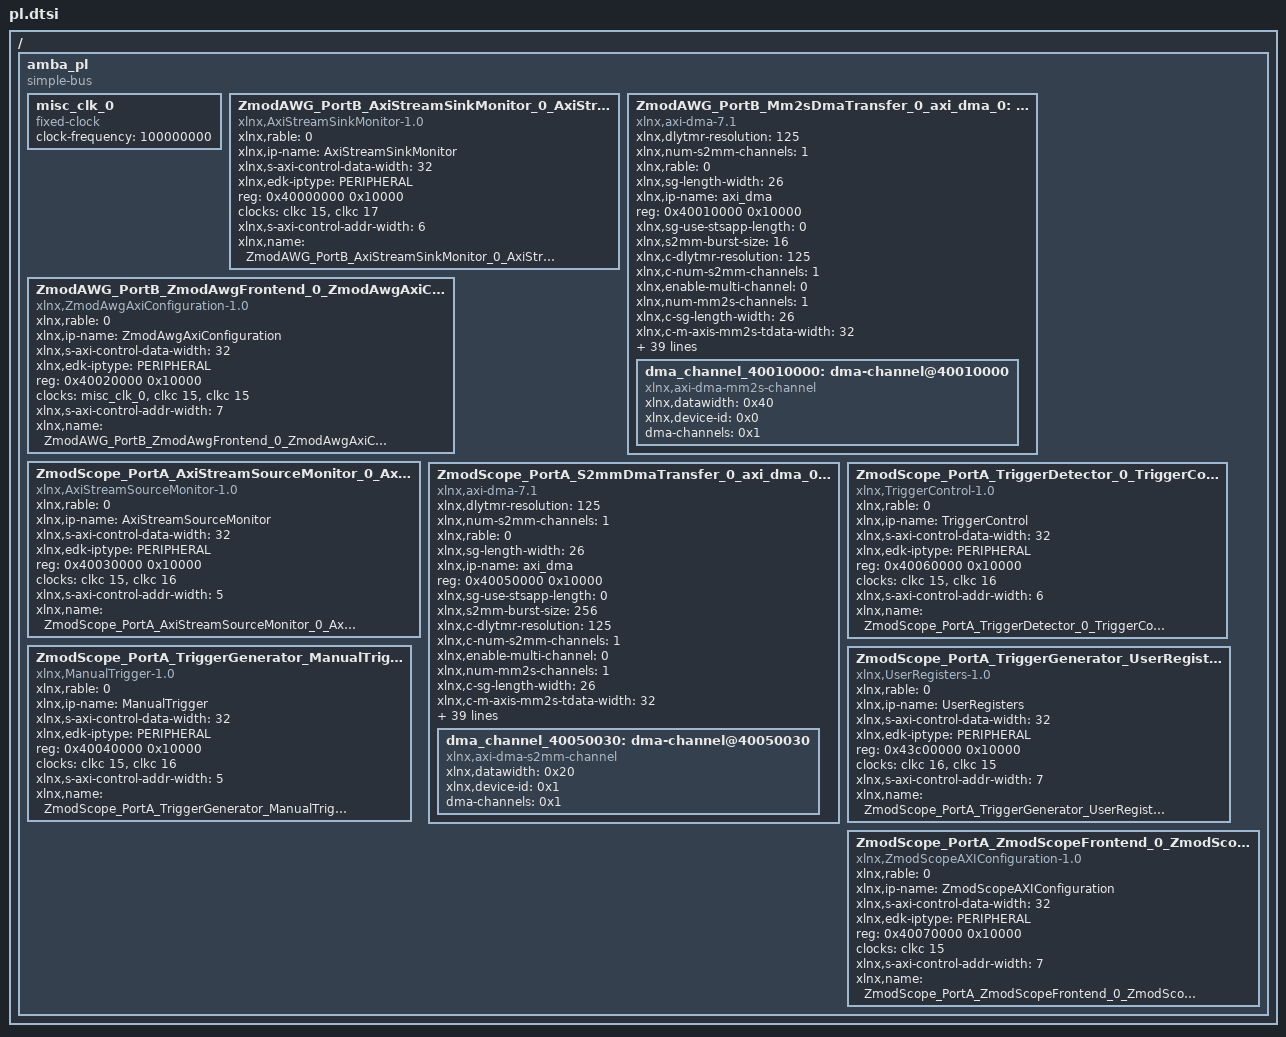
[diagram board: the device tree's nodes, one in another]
/ {
	amba_pl: amba_pl {
		ranges;
		compatible = "simple-bus";
		#address-cells = <1>;
		#size-cells = <1>;
		misc_clk_0: misc_clk_0 {
			compatible = "fixed-clock";
			clock-frequency = <100000000>;
			#clock-cells = <0>;
		};
		ZmodAWG_PortB_AxiStreamSinkMonitor_0_AxiStreamSinkMonitor_0: AxiStreamSinkMonitor@40000000 {
			xlnx,rable = <0>;
			compatible = "xlnx,AxiStreamSinkMonitor-1.0";
			status = "okay";
			clock-names = "s_axi_aclk" , "stream_clk";
			xlnx,ip-name = "AxiStreamSinkMonitor";
			xlnx,s-axi-control-data-width = <32>;
			xlnx,edk-iptype = "PERIPHERAL";
			reg = <0x40000000 0x10000>;
			clocks = <&clkc 15>, <&clkc 17>;
			xlnx,s-axi-control-addr-width = <6>;
			xlnx,name = "ZmodAWG_PortB_AxiStreamSinkMonitor_0_AxiStreamSinkMonitor_0";
		};
		ZmodAWG_PortB_Mm2sDmaTransfer_0_axi_dma_0: axi_dma@40010000 {
			xlnx,dlytmr-resolution = <125>;
			xlnx,num-s2mm-channels = <1>;
			xlnx,rable = <0>;
			xlnx,sg-length-width = <26>;
			xlnx,ip-name = "axi_dma";
			reg = <0x40010000 0x10000>;
			xlnx,sg-use-stsapp-length = <0>;
			xlnx,s2mm-burst-size = <16>;
			xlnx,c-dlytmr-resolution = <125>;
			xlnx,c-num-s2mm-channels = <1>;
			xlnx,enable-multi-channel = <0>;
			xlnx,num-mm2s-channels = <1>;
			xlnx,c-sg-length-width = <26>;
			compatible = "xlnx,axi-dma-7.1" , "xlnx,axi-dma-1.00.a";
			xlnx,c-m-axis-mm2s-tdata-width = <32>;
			xlnx,c-sg-use-stsapp-length = <0>;
			xlnx,c-s2mm-burst-size = <16>;
			xlnx,mm2s-burst-size = <256>;
			xlnx,c-enable-multi-channel = <0>;
			xlnx,c-num-mm2s-channels = <1>;
			xlnx,include-s2mm-dre = <0>;
			xlnx,include-sg;
			xlnx,c-mm2s-burst-size = <256>;
			status = "okay";
			xlnx,c-include-s2mm-dre = <0>;
			xlnx,include-mm2s-dre = <0>;
			xlnx,name = "ZmodAWG_PortB_Mm2sDmaTransfer_0_axi_dma_0";
			xlnx,c-include-sg = <1>;
			xlnx,c-m-axi-s2mm-data-width = <32>;
			xlnx,include-s2mm-sf = <1>;
			xlnx,c-include-mm2s-dre = <0>;
			xlnx,include-s2mm = <0>;
			clocks = <&clkc 18>, <&clkc 18>, <&clkc 15>;
			xlnx,addrwidth = <0x20>;
			xlnx,c-m-axi-mm2s-data-width = <64>;
			xlnx,edk-iptype = "PERIPHERAL";
			xlnx,c-include-s2mm-sf = <1>;
			xlnx,include-mm2s-sf = <1>;
			clock-names = "m_axi_mm2s_aclk" , "m_axi_sg_aclk" , "s_axi_lite_aclk";
			xlnx,c-include-s2mm = <0>;
			xlnx,c-addr-width = <32>;
			xlnx,c-single-interface = <0>;
			xlnx,include-mm2s = <1>;
			xlnx,c-s-axis-s2mm-tdata-width = <32>;
			xlnx,s2mm-data-width = <0x20>;
			xlnx,c-include-mm2s-sf = <1>;
			xlnx,prmry-is-aclk-async = <0>;
			xlnx,c-include-mm2s = <1>;
			xlnx,increase-throughput = <0>;
			xlnx,micro-dma = <0>;
			xlnx,mm2s-data-width = <0x40>;
			xlnx,c-prmry-is-aclk-async = <0>;
			xlnx,c-sg-include-stscntrl-strm = <0>;
			xlnx,c-increase-throughput = <0>;
			xlnx,c-micro-dma = <0>;
			dma_channel_40010000: dma-channel@40010000 {
				xlnx,datawidth = <0x40>;
				xlnx,device-id = <0x0>;
				compatible = "xlnx,axi-dma-mm2s-channel";
				dma-channels = <0x1>;
			};
		};
		ZmodAWG_PortB_ZmodAwgFrontend_0_ZmodAwgAxiConfigurat_0: ZmodAwgAxiConfiguration@40020000 {
			xlnx,rable = <0>;
			compatible = "xlnx,ZmodAwgAxiConfiguration-1.0";
			status = "okay";
			clock-names = "DAC_InIO_Clk" , "SysClk" , "s_axi_aclk";
			xlnx,ip-name = "ZmodAwgAxiConfiguration";
			xlnx,s-axi-control-data-width = <32>;
			xlnx,edk-iptype = "PERIPHERAL";
			reg = <0x40020000 0x10000>;
			clocks = <&misc_clk_0>, <&clkc 15>, <&clkc 15>;
			xlnx,s-axi-control-addr-width = <7>;
			xlnx,name = "ZmodAWG_PortB_ZmodAwgFrontend_0_ZmodAwgAxiConfigurat_0";
		};
		ZmodScope_PortA_AxiStreamSourceMonitor_0_AxiStreamSourceMonit_0: AxiStreamSourceMonitor@40030000 {
			xlnx,rable = <0>;
			compatible = "xlnx,AxiStreamSourceMonitor-1.0";
			status = "okay";
			clock-names = "s_axi_aclk" , "stream_clk";
			xlnx,ip-name = "AxiStreamSourceMonitor";
			xlnx,s-axi-control-data-width = <32>;
			xlnx,edk-iptype = "PERIPHERAL";
			reg = <0x40030000 0x10000>;
			clocks = <&clkc 15>, <&clkc 16>;
			xlnx,s-axi-control-addr-width = <5>;
			xlnx,name = "ZmodScope_PortA_AxiStreamSourceMonitor_0_AxiStreamSourceMonit_0";
		};
		ZmodScope_PortA_S2mmDmaTransfer_0_axi_dma_0: axi_dma@40050000 {
			xlnx,dlytmr-resolution = <125>;
			xlnx,num-s2mm-channels = <1>;
			xlnx,rable = <0>;
			xlnx,sg-length-width = <26>;
			xlnx,ip-name = "axi_dma";
			reg = <0x40050000 0x10000>;
			xlnx,sg-use-stsapp-length = <0>;
			xlnx,s2mm-burst-size = <256>;
			xlnx,c-dlytmr-resolution = <125>;
			xlnx,c-num-s2mm-channels = <1>;
			xlnx,enable-multi-channel = <0>;
			xlnx,num-mm2s-channels = <1>;
			xlnx,c-sg-length-width = <26>;
			compatible = "xlnx,axi-dma-7.1" , "xlnx,axi-dma-1.00.a";
			xlnx,c-m-axis-mm2s-tdata-width = <32>;
			xlnx,c-sg-use-stsapp-length = <0>;
			xlnx,c-s2mm-burst-size = <256>;
			xlnx,mm2s-burst-size = <16>;
			xlnx,c-enable-multi-channel = <0>;
			xlnx,c-num-mm2s-channels = <1>;
			xlnx,include-s2mm-dre = <0>;
			xlnx,include-sg;
			xlnx,c-mm2s-burst-size = <16>;
			status = "okay";
			xlnx,c-include-s2mm-dre = <0>;
			xlnx,include-mm2s-dre = <0>;
			xlnx,name = "ZmodScope_PortA_S2mmDmaTransfer_0_axi_dma_0";
			xlnx,c-include-sg = <1>;
			xlnx,c-m-axi-s2mm-data-width = <64>;
			xlnx,include-s2mm-sf = <1>;
			xlnx,c-include-mm2s-dre = <0>;
			xlnx,include-s2mm = <1>;
			clocks = <&clkc 18>, <&clkc 18>, <&clkc 15>;
			xlnx,addrwidth = <0x20>;
			xlnx,c-m-axi-mm2s-data-width = <32>;
			xlnx,edk-iptype = "PERIPHERAL";
			xlnx,c-include-s2mm-sf = <1>;
			xlnx,include-mm2s-sf = <1>;
			clock-names = "m_axi_s2mm_aclk" , "m_axi_sg_aclk" , "s_axi_lite_aclk";
			xlnx,c-include-s2mm = <1>;
			xlnx,c-addr-width = <32>;
			xlnx,c-single-interface = <0>;
			xlnx,include-mm2s = <0>;
			xlnx,c-s-axis-s2mm-tdata-width = <32>;
			xlnx,s2mm-data-width = <0x40>;
			xlnx,c-include-mm2s-sf = <1>;
			xlnx,prmry-is-aclk-async = <0>;
			xlnx,c-include-mm2s = <0>;
			xlnx,increase-throughput = <0>;
			xlnx,micro-dma = <0>;
			xlnx,mm2s-data-width = <0x20>;
			xlnx,c-prmry-is-aclk-async = <0>;
			xlnx,c-sg-include-stscntrl-strm = <0>;
			xlnx,c-increase-throughput = <0>;
			xlnx,c-micro-dma = <0>;
			dma_channel_40050030: dma-channel@40050030 {
				xlnx,datawidth = <0x20>;
				xlnx,device-id = <0x1>;
				compatible = "xlnx,axi-dma-s2mm-channel";
				dma-channels = <0x1>;
			};
		};
		ZmodScope_PortA_TriggerDetector_0_TriggerControl_0: TriggerControl@40060000 {
			xlnx,rable = <0>;
			compatible = "xlnx,TriggerControl-1.0";
			status = "okay";
			clock-names = "s_axi_aclk" , "stream_clk";
			xlnx,ip-name = "TriggerControl";
			xlnx,s-axi-control-data-width = <32>;
			xlnx,edk-iptype = "PERIPHERAL";
			reg = <0x40060000 0x10000>;
			clocks = <&clkc 15>, <&clkc 16>;
			xlnx,s-axi-control-addr-width = <6>;
			xlnx,name = "ZmodScope_PortA_TriggerDetector_0_TriggerControl_0";
		};
		ZmodScope_PortA_TriggerGenerator_ManualTrigger_0: ManualTrigger@40040000 {
			xlnx,rable = <0>;
			compatible = "xlnx,ManualTrigger-1.0";
			status = "okay";
			clock-names = "s_axi_aclk" , "stream_clk";
			xlnx,ip-name = "ManualTrigger";
			xlnx,s-axi-control-data-width = <32>;
			xlnx,edk-iptype = "PERIPHERAL";
			reg = <0x40040000 0x10000>;
			clocks = <&clkc 15>, <&clkc 16>;
			xlnx,s-axi-control-addr-width = <5>;
			xlnx,name = "ZmodScope_PortA_TriggerGenerator_ManualTrigger_0";
		};
		ZmodScope_PortA_TriggerGenerator_UserRegisters_0: UserRegisters@43c00000 {
			xlnx,rable = <0>;
			compatible = "xlnx,UserRegisters-1.0";
			status = "okay";
			clock-names = "io_clk" , "s_axi_aclk";
			xlnx,ip-name = "UserRegisters";
			xlnx,s-axi-control-data-width = <32>;
			xlnx,edk-iptype = "PERIPHERAL";
			reg = <0x43c00000 0x10000>;
			clocks = <&clkc 16>, <&clkc 15>;
			xlnx,s-axi-control-addr-width = <7>;
			xlnx,name = "ZmodScope_PortA_TriggerGenerator_UserRegisters_0";
		};
		ZmodScope_PortA_ZmodScopeFrontend_0_ZmodScopeAXIConfigur_0: ZmodScopeAXIConfiguration@40070000 {
			xlnx,rable = <0>;
			compatible = "xlnx,ZmodScopeAXIConfiguration-1.0";
			status = "okay";
			clock-names = "s_axi_control_clk";
			xlnx,ip-name = "ZmodScopeAXIConfiguration";
			xlnx,s-axi-control-data-width = <32>;
			xlnx,edk-iptype = "PERIPHERAL";
			reg = <0x40070000 0x10000>;
			clocks = <&clkc 15>;
			xlnx,s-axi-control-addr-width = <7>;
			xlnx,name = "ZmodScope_PortA_ZmodScopeFrontend_0_ZmodScopeAXIConfigur_0";
		};
	};
};
